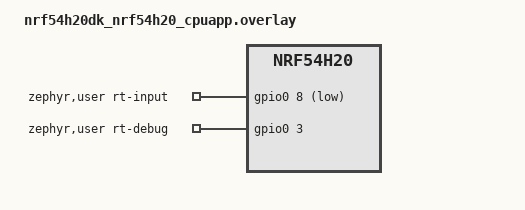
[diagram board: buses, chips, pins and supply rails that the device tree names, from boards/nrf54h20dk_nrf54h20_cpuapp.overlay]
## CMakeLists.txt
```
#
# Copyright (c) 2026 Nordic Semiconductor
#
# SPDX-License-Identifier: LicenseRef-Nordic-5-Clause
#

cmake_minimum_required(VERSION 3.20.0)
find_package(Zephyr REQUIRED HINTS $ENV{ZEPHYR_BASE})
project(rtfw_hid)

target_sources(app PRIVATE
  src/main.c
  src/hid_fastpath.c
)
```

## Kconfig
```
#
# Copyright (c) 2026 Nordic Semiconductor
#
# SPDX-License-Identifier: LicenseRef-Nordic-5-Clause
#

mainmenu "RTFW HID/GPIOTE backend"

config SAMPLE_RTFW_IRQ_PRIORITY
	int "GPIOTE zero-latency IRQ priority"
	default 1 if SOC_SERIES_NRF54L
	default 0
	range 0 7
	help
	  Select the priority of the sample-owned GPIOTE source interrupt.
	  nRF54L uses priority 1 so MPSL priority 0 can preempt it, while
	  nRF54H20 uses priority 0 because the radio runs on another core.

config SAMPLE_RTFW_ISR_TEST_LOAD
	bool "Inject a controlled busy loop into the GPIOTE fast path"
	help
	  Add a bounded NOP loop to the source ISR for stress and
	  coexistence measurements. The configured iteration count is
	  executed after the registered fast-path callback. Keep this
	  option disabled for baseline latency measurements.

config SAMPLE_RTFW_ISR_TEST_LOAD_CYCLES
	int "NOP iterations in the injected ISR load"
	depends on SAMPLE_RTFW_ISR_TEST_LOAD
	default 100
	range 1 1000000

config SAMPLE_RTFW_DEBUG_PIN
	bool "Expose GPIOTE ISR execution time on a debug pin"
	help
	  Drive the board-specific debug pin while the direct source ISR
	  executes so its latency and duration can be measured with a
	  logic analyzer. The output includes framework command handling
	  and the registered sample fast-path callback.

source "Kconfig.zephyr"
```

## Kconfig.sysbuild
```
#
# Copyright (c) 2026 Nordic Semiconductor
#
# SPDX-License-Identifier: LicenseRef-Nordic-5-Clause
#

config PARTITION_MANAGER
	default n

config NRF_DEFAULT_IPC_RADIO
	default y

config NETCORE_IPC_RADIO_BT_HCI_IPC
	default y

source "share/sysbuild/Kconfig"
```

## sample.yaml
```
sample:
  description: Event-driven RTFW GPIOTE input with Bluetooth HIDS delivery
  name: RTFW HID

tests:
  sample.rtfw.hid.nrf54l:
    build_only: true
    platform_allow:
      - nrf54lm20dk/nrf54lm20b/cpuapp
    integration_platforms:
      - nrf54lm20dk/nrf54lm20b/cpuapp
    tags:
      - bluetooth
      - rtfw

  sample.rtfw.hid.nrf54l.instrumentation:
    build_only: true
    platform_allow:
      - nrf54lm20dk/nrf54lm20b/cpuapp
    extra_configs:
      - CONFIG_SAMPLE_RTFW_DEBUG_PIN=y
      - CONFIG_SAMPLE_RTFW_ISR_TEST_LOAD=y
    tags:
      - bluetooth
      - rtfw

  sample.rtfw.hid.nrf54h20:
    sysbuild: true
    build_only: true
    platform_allow:
      - nrf54h20dk/nrf54h20/cpuapp
    integration_platforms:
      - nrf54h20dk/nrf54h20/cpuapp
    tags:
      - bluetooth
      - rtfw

  sample.rtfw.hid.nrf54h20.instrumentation:
    sysbuild: true
    build_only: true
    platform_allow:
      - nrf54h20dk/nrf54h20/cpuapp
    extra_configs:
      - CONFIG_SAMPLE_RTFW_DEBUG_PIN=y
      - CONFIG_SAMPLE_RTFW_ISR_TEST_LOAD=y
    tags:
      - bluetooth
      - rtfw
```

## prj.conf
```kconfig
#
# Copyright (c) 2026 Nordic Semiconductor
#
# SPDX-License-Identifier: LicenseRef-Nordic-5-Clause
#

CONFIG_NCS_SAMPLES_DEFAULTS=y
CONFIG_RTFW=y
CONFIG_RTFW_COMMAND_DATA_SIZE=4
CONFIG_ZERO_LATENCY_IRQS=y
CONFIG_ZERO_LATENCY_LEVELS=2
CONFIG_GPIO=n

CONFIG_BT=y
CONFIG_BT_PERIPHERAL=y
CONFIG_BT_DEVICE_NAME="Nordic_RTFW_HID"
CONFIG_BT_DEVICE_APPEARANCE=962
CONFIG_BT_HIDS=y
CONFIG_BT_HIDS_INPUT_REP_MAX=1
CONFIG_BT_HIDS_OUTPUT_REP_MAX=0
CONFIG_BT_HIDS_FEATURE_REP_MAX=0
CONFIG_BT_HIDS_ATTR_MAX=16
CONFIG_BT_HIDS_MAX_CLIENT_COUNT=1
CONFIG_BT_HIDS_DEFAULT_PERM_RW_ENCRYPT=y
CONFIG_BT_GATT_UUID16_POOL_SIZE=24
CONFIG_BT_GATT_CHRC_POOL_SIZE=12
CONFIG_BT_CONN_CTX=y
CONFIG_BT_SMP=y
CONFIG_BT_SETTINGS=y
CONFIG_SETTINGS=y

CONFIG_FLASH=y
CONFIG_FLASH_PAGE_LAYOUT=y
CONFIG_FLASH_MAP=y
CONFIG_ZMS=y
CONFIG_SETTINGS_ZMS=y

CONFIG_SYSTEM_WORKQUEUE_STACK_SIZE=2048
CONFIG_RTFW_WORKQ_STACK_SIZE=3072
```

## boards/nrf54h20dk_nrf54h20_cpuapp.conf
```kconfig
CONFIG_SOC_NRF54H20_CPURAD_ENABLE=y

# Radio notification connection callbacks are unavailable on the app core.
CONFIG_BT_RADIO_NOTIFICATION_CONN_CB=n

CONFIG_ZERO_LATENCY_LEVELS=1
CONFIG_SAMPLE_RTFW_IRQ_PRIORITY=0
```

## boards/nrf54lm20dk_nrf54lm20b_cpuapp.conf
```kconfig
CONFIG_SAMPLE_RTFW_IRQ_PRIORITY=1
```

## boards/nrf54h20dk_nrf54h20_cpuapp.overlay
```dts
/*
 * Copyright (c) 2026 Nordic Semiconductor
 *
 * SPDX-License-Identifier: LicenseRef-Nordic-5-Clause
 */

#include <zephyr/dt-bindings/gpio/gpio.h>

/ {
	aliases {
		rt-gpiote = &gpiote130;
		rt-egu = &egu130;
	};

	zephyr,user {
		rt-input-gpios = <&gpio0 8 (GPIO_ACTIVE_LOW | GPIO_PULL_UP)>;
		rt-debug-gpios = <&gpio0 3 GPIO_ACTIVE_HIGH>;
	};
};

&gpiote130 {
	status = "reserved";
};

&egu130 {
	status = "reserved";
};

&gpio0 {
	status = "okay";
};
```

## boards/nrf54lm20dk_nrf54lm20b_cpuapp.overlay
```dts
/*
 * Copyright (c) 2026 Nordic Semiconductor
 *
 * SPDX-License-Identifier: LicenseRef-Nordic-5-Clause
 */

#include <zephyr/dt-bindings/gpio/gpio.h>

/ {
	aliases {
		rt-gpiote = &gpiote20;
		rt-egu = &egu20;
	};

	zephyr,user {
		rt-input-gpios = <&gpio1 26 (GPIO_ACTIVE_LOW | GPIO_PULL_UP)>;
		rt-debug-gpios = <&gpio1 7 GPIO_ACTIVE_HIGH>;
	};
};

/* Exclusively owned by the RTFW HID backend. */
&gpiote20 {
	status = "disabled";
};

&egu20 {
	status = "disabled";
};
```

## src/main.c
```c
/*
 * Copyright (c) 2026 Nordic Semiconductor
 *
 * SPDX-License-Identifier: LicenseRef-Nordic-5-Clause
 */

#include <limits.h>
#include <string.h>
#include <zephyr/kernel.h>
#include <zephyr/settings/settings.h>
#include <zephyr/sys/printk.h>
#include <zephyr/bluetooth/bluetooth.h>
#include <zephyr/bluetooth/conn.h>
#include <zephyr/bluetooth/gatt.h>
#include <zephyr/bluetooth/hci.h>
#include <zephyr/bluetooth/uuid.h>
#include <bluetooth/services/hids.h>
#include <hal/nrf_grtc.h>

#include "hid_internal.h"
#include "hid_platform.h"

#define HID_REPORT_SIZE  3U
#define HID_REPORT_ID    1U
#define HID_REPORT_INDEX 0U
#define BASE_USB_HID_SPEC_VERSION 0x0101
#define LATENCY_HISTOGRAM_BINS   256U
#define LATENCY_HISTOGRAM_BIN_US 8U
#define LATENCY_REPORT_SAMPLES   128U
#define LATENCY_HISTOGRAM_RANGE_US \
	(LATENCY_HISTOGRAM_BINS * LATENCY_HISTOGRAM_BIN_US)

BT_HIDS_DEF(hids, HID_REPORT_SIZE);

static K_MUTEX_DEFINE(connection_lock);
static struct bt_conn *active_connection;
static struct k_work advertising_work;

static uint32_t latency_min_us = UINT32_MAX;
static uint32_t latency_max_us;
static uint64_t latency_sum_us;
static uint32_t latency_samples;
static uint32_t latency_histogram_overflows;
static uint32_t hids_window_drops;
static int hids_send_last_error;
static uint32_t latency_histogram[LATENCY_HISTOGRAM_BINS];

static const uint8_t report_map[] = {
	0x05, 0x01,       /* Usage Page (Generic Desktop) */
	0x09, 0x02,       /* Usage (Mouse) */
	0xA1, 0x01,       /* Collection (Application) */
	0x85, HID_REPORT_ID,
	0x09, 0x01,       /* Usage (Pointer) */
	0xA1, 0x00,       /* Collection (Physical) */
	0x05, 0x09,       /* Usage Page (Buttons) */
	0x19, 0x01,
	0x29, 0x03,
	0x15, 0x00,
	0x25, 0x01,
	0x95, 0x03,
	0x75, 0x01,
	0x81, 0x02,
	0x95, 0x01,       /* Five bits padding */
	0x75, 0x05,
	0x81, 0x01,
	0x05, 0x01,
	0x09, 0x30,       /* X */
	0x09, 0x31,       /* Y */
	0x15, 0x81,
	0x25, 0x7f,
	0x75, 0x08,
	0x95, 0x02,
	0x81, 0x06,
	0xC0,
	0xC0,
};

static const struct bt_data advertising_data[] = {
	BT_DATA_BYTES(BT_DATA_GAP_APPEARANCE,
		      (CONFIG_BT_DEVICE_APPEARANCE >> 0) & 0xff,
		      (CONFIG_BT_DEVICE_APPEARANCE >> 8) & 0xff),
	BT_DATA_BYTES(BT_DATA_FLAGS, BT_LE_AD_GENERAL | BT_LE_AD_NO_BREDR),
	BT_DATA_BYTES(BT_DATA_UUID16_ALL, BT_UUID_16_ENCODE(BT_UUID_HIDS_VAL)),
};

static const struct bt_data scan_data[] = {
	BT_DATA(BT_DATA_NAME_COMPLETE, CONFIG_BT_DEVICE_NAME,
		sizeof(CONFIG_BT_DEVICE_NAME) - 1),
};

static void advertising_handler(struct k_work *work)
{
	int error;

	ARG_UNUSED(work);
	error = bt_le_adv_start(BT_LE_ADV_CONN_FAST_2, advertising_data,
				ARRAY_SIZE(advertising_data), scan_data,
				ARRAY_SIZE(scan_data));
	printk("HID advertising start: %d\n", error);
}

static void connected(struct bt_conn *connection, uint8_t error)
{
	int hids_error;
	int security_error;

	if (error != 0U) {
		return;
	}

	hids_error = bt_hids_connected(&hids, connection);
	if (hids_error != 0) {
		printk("HIDS connection setup failed: %d\n", hids_error);
		return;
	}

	k_mutex_lock(&connection_lock, K_FOREVER);
	if (active_connection == NULL) {
		active_connection = bt_conn_ref(connection);
	}
	k_mutex_unlock(&connection_lock);

	security_error = bt_conn_set_security(connection, BT_SECURITY_L2);
	if (security_error != 0) {
		printk("HID security request failed: %d\n", security_error);
	}
}

static void disconnected(struct bt_conn *connection, uint8_t reason)
{
	int error;

	ARG_UNUSED(reason);
	error = bt_hids_disconnected(&hids, connection);
	if (error != 0) {
		printk("HIDS disconnection cleanup failed: %d\n", error);
	}

	k_mutex_lock(&connection_lock, K_FOREVER);
	if (active_connection == connection) {
		bt_conn_unref(active_connection);
		active_connection = NULL;
	}
	k_mutex_unlock(&connection_lock);
}

static void connection_recycled(void)
{
	k_work_submit(&advertising_work);
}

BT_CONN_CB_DEFINE(connection_callbacks) = {
	.connected = connected,
	.disconnected = disconnected,
	.recycled = connection_recycled,
};

static int hids_init(void)
{
	struct bt_hids_init_param parameters = {0};
	struct bt_hids_inp_rep *input_report =
		&parameters.inp_rep_group_init.reports[0];

	parameters.rep_map.data = report_map;
	parameters.rep_map.size = sizeof(report_map);
	parameters.info.bcd_hid = BASE_USB_HID_SPEC_VERSION;
	parameters.info.flags =
		BT_HIDS_REMOTE_WAKE | BT_HIDS_NORMALLY_CONNECTABLE;
	input_report->size = HID_REPORT_SIZE;
	input_report->id = HID_REPORT_ID;
	parameters.inp_rep_group_init.cnt = 1U;
	parameters.is_mouse = true;

	return bt_hids_init(&hids, &parameters);
}

static void latency_record(uint32_t edge_timestamp_us)
{
	uint32_t latency_us =
		nrf_grtc_sys_counter_low_get(NRF_GRTC) - edge_timestamp_us;
	uint32_t histogram_index = MIN(latency_us / LATENCY_HISTOGRAM_BIN_US,
				       LATENCY_HISTOGRAM_BINS - 1U);

	latency_min_us = MIN(latency_min_us, latency_us);
	latency_max_us = MAX(latency_max_us, latency_us);
	latency_sum_us += latency_us;
	latency_samples++;
	latency_histogram[histogram_index]++;
	if (latency_us >= LATENCY_HISTOGRAM_RANGE_US) {
		latency_histogram_overflows++;
	}

	if (latency_samples == LATENCY_REPORT_SAMPLES) {
		struct rtfw_status framework_status = {0};
		uint32_t cumulative = 0U;
		uint32_t median_index = 0U;
		uint32_t median_lb_us;
		int status_error;

		for (; median_index < LATENCY_HISTOGRAM_BINS; median_index++) {
			cumulative += latency_histogram[median_index];
			if (cumulative >= DIV_ROUND_UP(latency_samples, 2U)) {
				break;
			}
		}
		median_lb_us = median_index * LATENCY_HISTOGRAM_BIN_US;
		status_error = rtfw_get_status(&framework_status);
		printk("HID edge->HIDS submit us: avg=%llu median_lb=%u min=%u "
		       "max=%u jitter=%u hist_overflows=%u "
		       "hids_window_drops=%u last_hids_err=%d "
		       "rtfw_drops=%u rtfw_max_depth=%u "
		       "rtfw_faults=0x%08x rtfw_status_err=%d\n",
		       latency_sum_us / latency_samples, median_lb_us,
		       latency_min_us, latency_max_us,
		       latency_max_us - latency_min_us,
		       latency_histogram_overflows, hids_window_drops,
		       hids_send_last_error, framework_status.dropped_events,
		       framework_status.max_queue_depth, framework_status.faults,
		       status_error);

		latency_min_us = UINT32_MAX;
		latency_max_us = 0U;
		latency_sum_us = 0U;
		latency_samples = 0U;
		latency_histogram_overflows = 0U;
		hids_window_drops = 0U;
		hids_send_last_error = 0;
		memset(latency_histogram, 0, sizeof(latency_histogram));
	}
}

static void rtfw_event_handler(const struct rtfw_event *event, void *user_data)
{
	struct bt_conn *connection = NULL;
	uint8_t report[HID_REPORT_SIZE] = {0};
	int error;

	ARG_UNUSED(user_data);
	if (event->type != RTFW_HID_EVENT_EDGE) {
		return;
	}

	k_mutex_lock(&connection_lock, K_FOREVER);
	if (active_connection != NULL) {
		connection = bt_conn_ref(active_connection);
	}
	k_mutex_unlock(&connection_lock);

	if (connection == NULL) {
		return;
	}

	report[0] = event->value != 0U ? 1U : 0U;
	report[1] = event->value != 0U ? 8U : 0U;
	error = bt_hids_inp_rep_send(&hids, connection, HID_REPORT_INDEX,
				     report, sizeof(report), NULL);
	if (error != 0) {
		hids_window_drops++;
		hids_send_last_error = error;
	}
	latency_record(event->timestamp);
	bt_conn_unref(connection);
}

static int fastpath_enable(void)
{
	struct rtfw_hid_config config = {.enabled = 1U};
	struct rtfw_command command = {
		.id = RTFW_HID_COMMAND_CONFIGURE,
		.data_len = sizeof(config),
	};

	memcpy(command.data, &config, sizeof(config));
	return rtfw_submit(&command);
}

int main(void)
{
	const struct rtfw_config framework_config = {
		.command_handler = rtfw_hid_command_handler,
		.fastpath_handler = rtfw_hid_fastpath_handler,
		.pend_source_irq = rtfw_hid_pend_source_irq,
		.event_handler = rtfw_event_handler,
	};
	int error;

	printk("Starting event-driven RTFW HID/GPIOTE backend\n");
	error = rtfw_init(&framework_config);
	if (error != 0) {
		return error;
	}
	rtfw_hid_fastpath_init();

	error = hids_init();
	if (error != 0) {
		return error;
	}
	error = bt_enable(NULL);
	if (error != 0) {
		return error;
	}
	(void)settings_load();

	k_work_init(&advertising_work, advertising_handler);
	k_work_submit(&advertising_work);

	error = fastpath_enable();
	if (error != 0) {
		return error;
	}

	return 0;
}
```

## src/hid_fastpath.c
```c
/*
 * Copyright (c) 2026 Nordic Semiconductor
 *
 * SPDX-License-Identifier: LicenseRef-Nordic-5-Clause
 */

#include <errno.h>
#include <string.h>
#include <cmsis_core.h>
#include <zephyr/irq.h>
#include <hal/nrf_gpio.h>
#include <hal/nrf_gpiote.h>
#include <hal/nrf_grtc.h>

#include "hid_internal.h"
#include "hid_platform.h"

#define GPIOTE_CHANNEL 0U
#define GPIOTE_MASK    (1UL << GPIOTE_CHANNEL)

static bool input_enabled;

static void gpiote_interrupt_enable(void)
{
#if NRF_GPIOTE_HAS_INT_GROUPS
	nrf_gpiote_int_group_enable(RTFW_GPIOTE, NRF_GPIOTE_IRQ_GROUP,
				    GPIOTE_MASK);
#else
	nrf_gpiote_int_enable(RTFW_GPIOTE, GPIOTE_MASK);
#endif
}

static void gpiote_interrupt_disable(void)
{
#if NRF_GPIOTE_HAS_INT_GROUPS
	nrf_gpiote_int_group_disable(RTFW_GPIOTE, NRF_GPIOTE_IRQ_GROUP,
				     GPIOTE_MASK);
#else
	nrf_gpiote_int_disable(RTFW_GPIOTE, GPIOTE_MASK);
#endif
}

int rtfw_hid_command_handler(const struct rtfw_command *command,
			     void *user_data)
{
	struct rtfw_hid_config config;
	nrf_gpiote_event_t event = nrf_gpiote_in_event_get(GPIOTE_CHANNEL);

	ARG_UNUSED(user_data);
	if (command->id != RTFW_HID_COMMAND_CONFIGURE ||
	    command->data_len != sizeof(struct rtfw_hid_config)) {
		return -EINVAL;
	}

	memcpy(&config, command->data, sizeof(config));
	bool enable = config.enabled != 0U;

	if (enable == input_enabled) {
		return 0;
	}

	if (enable) {
		nrf_gpiote_event_clear(RTFW_GPIOTE, event);
		nrf_gpiote_event_enable(RTFW_GPIOTE, GPIOTE_CHANNEL);
		gpiote_interrupt_enable();
	} else {
		gpiote_interrupt_disable();
		nrf_gpiote_event_disable(RTFW_GPIOTE, GPIOTE_CHANNEL);
		nrf_gpiote_event_clear(RTFW_GPIOTE, event);
	}
	input_enabled = enable;

	return 0;
}

void rtfw_hid_pend_source_irq(void *user_data)
{
	ARG_UNUSED(user_data);
	NVIC_SetPendingIRQ(RTFW_GPIOTE_IRQN);
}

void rtfw_hid_fastpath_handler(void *user_data)
{
	nrf_gpiote_event_t source = nrf_gpiote_in_event_get(GPIOTE_CHANNEL);
	bool hardware_event = nrf_gpiote_event_check(RTFW_GPIOTE, source);

	ARG_UNUSED(user_data);
	if (hardware_event) {
		nrf_gpiote_event_clear(RTFW_GPIOTE, source);
	}

	if (hardware_event && input_enabled) {
		struct rtfw_event event = {
			.type = RTFW_HID_EVENT_EDGE,
			.value = ((nrf_gpio_pin_read(RTFW_INPUT_ABS) != 0U) !=
				  RTFW_INPUT_ACTIVE_LOW),
			.timestamp = nrf_grtc_sys_counter_low_get(NRF_GRTC),
		};

		(void)rtfw_event_push(&event);
	}
}

ISR_DIRECT_DECLARE(rtfw_hid_isr)
{
#if defined(CONFIG_SAMPLE_RTFW_DEBUG_PIN)
	nrf_gpio_pin_set(RTFW_DEBUG_GPIO_ABS);
#endif

	rtfw_fastpath_run();

#if defined(CONFIG_SAMPLE_RTFW_ISR_TEST_LOAD)
	for (uint32_t i = 0U;
	     i < CONFIG_SAMPLE_RTFW_ISR_TEST_LOAD_CYCLES; i++) {
		__NOP();
	}
#endif

#if defined(CONFIG_SAMPLE_RTFW_DEBUG_PIN)
	nrf_gpio_pin_clear(RTFW_DEBUG_GPIO_ABS);
#endif

	return 0;
}

void rtfw_hid_fastpath_init(void)
{
	input_enabled = false;

	nrf_gpio_cfg_input(RTFW_INPUT_ABS, RTFW_INPUT_PULL);
	nrf_gpiote_event_configure(RTFW_GPIOTE, GPIOTE_CHANNEL, RTFW_INPUT_ABS,
				   NRF_GPIOTE_POLARITY_TOGGLE);
	nrf_gpiote_event_disable(RTFW_GPIOTE, GPIOTE_CHANNEL);
	gpiote_interrupt_disable();
	nrf_gpiote_event_clear(RTFW_GPIOTE,
			       nrf_gpiote_in_event_get(GPIOTE_CHANNEL));

#if defined(CONFIG_SAMPLE_RTFW_DEBUG_PIN)
	nrf_gpio_cfg_output(RTFW_DEBUG_GPIO_ABS);
	nrf_gpio_pin_clear(RTFW_DEBUG_GPIO_ABS);
#endif

	IRQ_DIRECT_CONNECT(RTFW_GPIOTE_IRQN, CONFIG_SAMPLE_RTFW_IRQ_PRIORITY,
			   rtfw_hid_isr, IRQ_ZERO_LATENCY);
	irq_enable(RTFW_GPIOTE_IRQN);
}
```

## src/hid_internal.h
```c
/*
 * Copyright (c) 2026 Nordic Semiconductor
 *
 * SPDX-License-Identifier: LicenseRef-Nordic-5-Clause
 */

#ifndef RTFW_HID_INTERNAL_H_
#define RTFW_HID_INTERNAL_H_

#include <stdint.h>
#include <zephyr/sys/util.h>
#include <rtfw/rtfw.h>

#define RTFW_HID_COMMAND_CONFIGURE 1U
#define RTFW_HID_EVENT_EDGE        (RTFW_EVENT_TYPE_USER_BASE + 0x100U)

struct rtfw_hid_config {
	uint32_t enabled;
};

BUILD_ASSERT(sizeof(struct rtfw_hid_config) <=
	     CONFIG_RTFW_COMMAND_DATA_SIZE,
	     "RTFW command payload is too small for the HID configuration");

int rtfw_hid_command_handler(const struct rtfw_command *command,
			     void *user_data);
void rtfw_hid_fastpath_handler(void *user_data);
void rtfw_hid_pend_source_irq(void *user_data);
void rtfw_hid_fastpath_init(void);

#endif /* RTFW_HID_INTERNAL_H_ */
```

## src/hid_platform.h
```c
/*
 * Copyright (c) 2026 Nordic Semiconductor
 *
 * SPDX-License-Identifier: LicenseRef-Nordic-5-Clause
 */

#ifndef RTFW_HID_PLATFORM_H_
#define RTFW_HID_PLATFORM_H_

#include <zephyr/devicetree.h>
#include <zephyr/dt-bindings/gpio/gpio.h>
#include <zephyr/irq.h>
#include <soc.h>
#include <hal/nrf_gpiote.h>

#define RTFW_GPIOTE_NODE DT_ALIAS(rt_gpiote)
#define RTFW_USER_NODE   DT_PATH(zephyr_user)

BUILD_ASSERT(DT_NODE_EXISTS(RTFW_GPIOTE_NODE),
	     "HID backend requires the rt-gpiote alias");
BUILD_ASSERT(CONFIG_SAMPLE_RTFW_IRQ_PRIORITY < ZERO_LATENCY_LEVELS,
	     "RTFW priority must be inside the zero-latency priority range");
BUILD_ASSERT(!IS_ENABLED(CONFIG_PM),
	     "HID sample does not support system PM");
#if defined(CONFIG_SOC_SERIES_NRF54L)
BUILD_ASSERT(CONFIG_SAMPLE_RTFW_IRQ_PRIORITY == 1,
	     "nRF54L RTFW must leave priority 0 to MPSL");
#else
BUILD_ASSERT(CONFIG_SAMPLE_RTFW_IRQ_PRIORITY == 0,
	     "nRF54H20 app-core RTFW must use priority 0");
#endif

#define RTFW_GPIOTE      ((NRF_GPIOTE_Type *)DT_REG_ADDR(RTFW_GPIOTE_NODE))
#define RTFW_GPIOTE_IRQN DT_IRQN(RTFW_GPIOTE_NODE)
#define RTFW_INPUT_ABS   NRF_DT_GPIOS_TO_PSEL(RTFW_USER_NODE, rt_input_gpios)
#define RTFW_INPUT_FLAGS DT_GPIO_FLAGS(RTFW_USER_NODE, rt_input_gpios)
#define RTFW_INPUT_ACTIVE_LOW \
	((RTFW_INPUT_FLAGS & GPIO_ACTIVE_LOW) != 0U)
#define RTFW_INPUT_PULL                                                    \
	((RTFW_INPUT_FLAGS & GPIO_PULL_UP) != 0U ? NRF_GPIO_PIN_PULLUP :   \
	 (RTFW_INPUT_FLAGS & GPIO_PULL_DOWN) != 0U ? NRF_GPIO_PIN_PULLDOWN : \
						     NRF_GPIO_PIN_NOPULL)

BUILD_ASSERT((RTFW_INPUT_FLAGS & (GPIO_PULL_UP | GPIO_PULL_DOWN)) !=
		     (GPIO_PULL_UP | GPIO_PULL_DOWN),
	     "rt-input-gpios cannot request both pull-up and pull-down");

#if defined(CONFIG_SAMPLE_RTFW_DEBUG_PIN)
#define RTFW_DEBUG_GPIO_ABS NRF_DT_GPIOS_TO_PSEL(RTFW_USER_NODE, rt_debug_gpios)
#endif

#endif /* RTFW_HID_PLATFORM_H_ */
```
